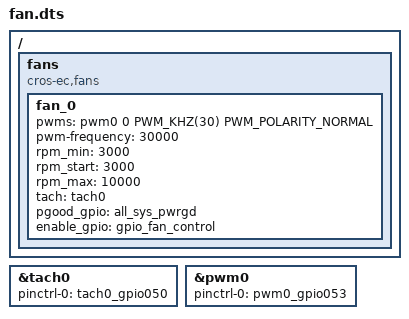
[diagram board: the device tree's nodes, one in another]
/* Copyright 2022 The Chromium OS Authors. All rights reserved.
 * Use of this source code is governed by a BSD-style license that can be
 * found in the LICENSE file.
 */

/ {
	fans {
		compatible = "cros-ec,fans";

		fan_0 {
			pwms = <&pwm0 0 PWM_KHZ(30) PWM_POLARITY_NORMAL>;
			pwm-frequency = <30000>;
			rpm_min = <3000>;
			rpm_start = <3000>;
			rpm_max = <10000>;
			tach = <&tach0>;
			pgood_gpio = <&all_sys_pwrgd>;
			enable_gpio = <&gpio_fan_control>;
		};
	};
};

/* Tachemeter for fan speed measurement */
&tach0 {
	status = "okay";
	pinctrl-0 = <&tach0_gpio050>;
	pinctrl-names = "default";
};

&pwm0 {
	status = "okay";
	pinctrl-0 = <&pwm0_gpio053>;
	pinctrl-names = "default";
};
